AUTOSAR XML (schema 314)
package /ComponentType
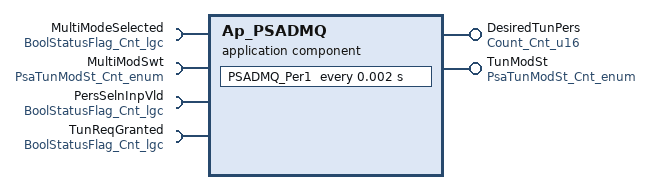
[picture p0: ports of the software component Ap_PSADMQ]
  application software component type Ap_PSADMQ
    provide port DesiredTunPers: unqueued-sender-com-spec{data-element=Cnt_u16, can-invalidate=false, init-value=D_ZERO_CNT_U16}, provided-interface=Count_Cnt_u16  # Desired Tuning Personality
    provide port TunModSt: unqueued-sender-com-spec{data-element=Cnt_enum, can-invalidate=false, init-value=D_PSATUNMODSTINIT_CNT_ENUM}, provided-interface=PsaTunModSt_Cnt_enum  # Tuning Mode State Output
    4 x require port:
      MultiModeSelected: unqueued-receiver-com-spec{data-element=Cnt_lgc, init-value=D_FALSE_CNT_LGC}, required-interface=BoolStatusFlag_Cnt_lgc  # Variant coding signal to enable/disable multimode function
      MultiModSwt: unqueued-receiver-com-spec{data-element=Cnt_enum, init-value=D_PSATUNMODSTINIT_CNT_ENUM}, required-interface=PsaTunModSt_Cnt_enum  # CAN signal to switch between the tuning mode
      PersSelnInpVld: unqueued-receiver-com-spec{data-element=Cnt_lgc, init-value=D_FALSE_CNT_LGC}, required-interface=BoolStatusFlag_Cnt_lgc  # Check if the CAN signal used by multimode is valid
      TunReqGranted: unqueued-receiver-com-spec{data-element=Cnt_lgc, init-value=D_FALSE_CNT_LGC}, required-interface=BoolStatusFlag_Cnt_lgc  # Indicates whether request is granted for tuning set or personality change. TRUE = Request granted, FALSE = Request denied
  internal behavior Ap_PSADMQ_InternalBehavior: component=Ap_PSADMQ
    timing event TMT_PSADMQ_Per1: start-on-event=PSADMQ_Per1, period=0.002
    port-api-options:
      enable-take-address=false, indirect-api=false, port=DesiredTunPers
      enable-take-address=false, indirect-api=false, port=MultiModeSelected
      enable-take-address=false, indirect-api=false, port=MultiModSwt
      enable-take-address=false, indirect-api=false, port=PersSelnInpVld
      enable-take-address=false, indirect-api=false, port=TunModSt
      enable-take-address=false, indirect-api=false, port=TunReqGranted
    runnable PSADMQ_Per1
      4 x data read access:
        READ_MultiModeSelected_Cnt_lgc: data-element=MultiModeSelected.Cnt_lgc
        READ_MultiModSwt_Cnt_enum: data-element=MultiModSwt.Cnt_enum
        READ_PersSelnInpVld_Cnt_lgc: data-element=PersSelnInpVld.Cnt_lgc
        READ_TunReqGranted_Cnt_lgc: data-element=TunReqGranted.Cnt_lgc
      data write access WRITE_DesiredTunPers_Cnt_u16: data-element=DesiredTunPers.Cnt_u16
      data write access WRITE_TunModSt_Cnt_enum: data-element=TunModSt.Cnt_enum
  swc implementation Ap_PSADMQ_Implementation: behavior=Ap_PSADMQ_InternalBehavior
    code-descriptors:
      code Code: type=SRC
